# LM3S1969 register map
File version: 7944
Registers are 32-bit, read-write, no defined reset value unless marked. A register's access mark holds for its fields unless they carry their own. Offsets are from the block's base; [hi:lo] are bit positions; {n}, {i} and the like mark numbered series.

## ADC0 — Register map for ADC0 peripheral
Base 0x40038000; register names take the prefix ADC0
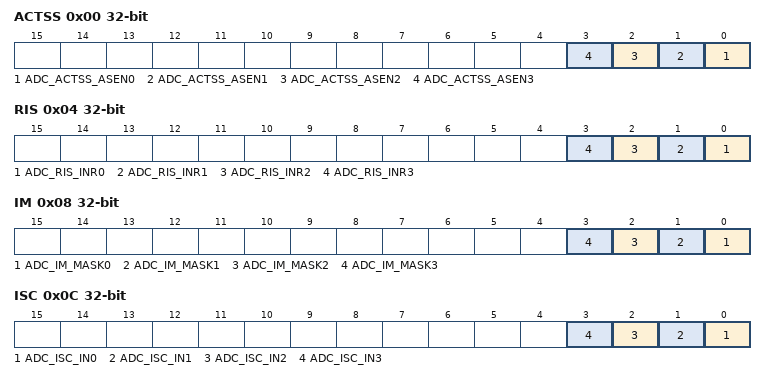
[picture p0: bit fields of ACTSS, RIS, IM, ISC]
0x00 ACTSS — ADC Active Sample Sequencer
  [n] ADC_ACTSS_ASEN{n} (n=0..3) — ADC SS{n} Enable
0x04 RIS — ADC Raw Interrupt Status
  [n] ADC_RIS_INR{n} (n=0..3) — SS{n} Raw Interrupt Status
0x08 IM — ADC Interrupt Mask
  [n] ADC_IM_MASK{n} (n=0..3) — SS{n} Interrupt Mask
0x0C ISC — ADC Interrupt Status and Clear
  [n] ADC_ISC_IN{n} (n=0..3) — SS{n} Interrupt Status and Clear
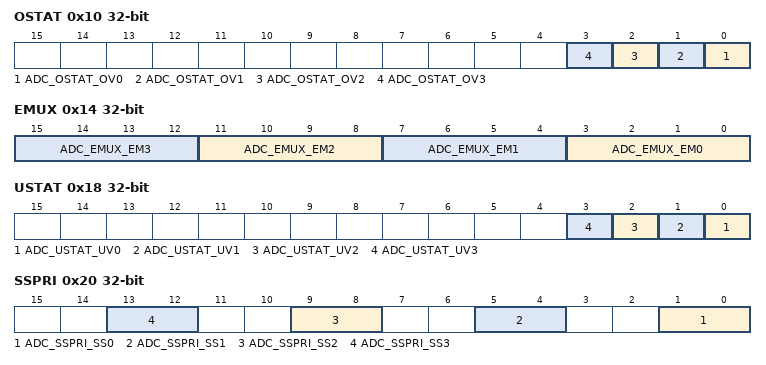
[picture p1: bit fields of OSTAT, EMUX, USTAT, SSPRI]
0x10 OSTAT — ADC Overflow Status
  [n] ADC_OSTAT_OV{n} (n=0..3) — SS{n} FIFO Overflow
0x14 EMUX — ADC Event Multiplexer Select
  [4n+3:4n] ADC_EMUX_EM{n} (n=0..3) — SS{n} Trigger Select
    0=ADC_EMUX_EM{n}_PROCESSOR (Processor (default)); 1=ADC_EMUX_EM{n}_COMP0 (Analog Comparator 0); 2=ADC_EMUX_EM{n}_COMP1 (Analog Comparator 1); 3=ADC_EMUX_EM{n}_COMP2 (Analog Comparator 2); 4=ADC_EMUX_EM{n}_EXTERNAL (External (GPIO PB4)); 5=ADC_EMUX_EM{n}_TIMER (Timer); 6=ADC_EMUX_EM{n}_PWM0 (PWM0); 7=ADC_EMUX_EM{n}_PWM1 (PWM1); 8=ADC_EMUX_EM{n}_PWM2 (PWM2); 15=ADC_EMUX_EM{n}_ALWAYS (Always (continuously sample))
0x18 USTAT — ADC Underflow Status
  [n] ADC_USTAT_UV{n} (n=0..3) — SS{n} FIFO Underflow
0x20 SSPRI — ADC Sample Sequencer Priority
  [4n+1:4n] ADC_SSPRI_SS{n} (n=0..3) — SS{n} Priority
    0=ADC_SSPRI_SS{n}_1ST (First priority); 1=ADC_SSPRI_SS{n}_2ND (Second priority); 2=ADC_SSPRI_SS{n}_3RD (Third priority); 3=ADC_SSPRI_SS{n}_4TH (Fourth priority)
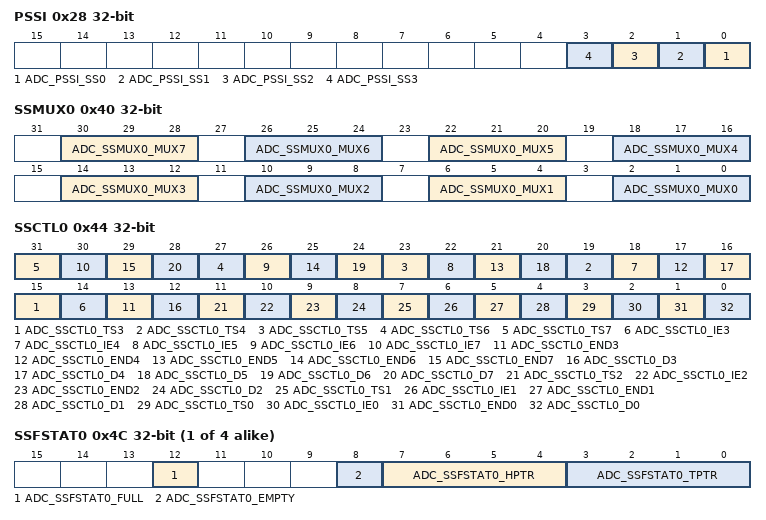
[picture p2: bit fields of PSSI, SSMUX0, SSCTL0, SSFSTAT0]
0x28 PSSI — ADC Processor Sample Sequence Initiate
  [n] ADC_PSSI_SS{n} (n=0..3) — SS{n} Initiate
0x30 SAC — ADC Sample Averaging Control
  [2:0] ADC_SAC_AVG — Hardware Averaging Control
    0=ADC_SAC_AVG_OFF (No hardware oversampling); 1=ADC_SAC_AVG_2X (2x hardware oversampling); 2=ADC_SAC_AVG_4X (4x hardware oversampling); 3=ADC_SAC_AVG_8X (8x hardware oversampling); 4=ADC_SAC_AVG_16X (16x hardware oversampling); 5=ADC_SAC_AVG_32X (32x hardware oversampling); 6=ADC_SAC_AVG_64X (64x hardware oversampling)
0x40 SSMUX0 — ADC Sample Sequence Input Multiplexer Select 0
  [4n+2:4n] ADC_SSMUX0_MUX{n} (n=3..7) — {n+1}th Sample Input Select
  [10:8] ADC_SSMUX0_MUX2 — 3rd Sample Input Select
  [6:4] ADC_SSMUX0_MUX1 — 2nd Sample Input Select
  [2:0] ADC_SSMUX0_MUX0 — 1st Sample Input Select
0x44 SSCTL0 — ADC Sample Sequence Control 0
  [4n+3] ADC_SSCTL0_TS{n} (n=3..7) — {n+1}th Sample Temp Sensor Select
  [4n+2] ADC_SSCTL0_IE{n} (n=3..7) — {n+1}th Sample Interrupt Enable
  [4n+1] ADC_SSCTL0_END{n} (n=3..7) — {n+1}th Sample is End of Sequence
  [4n] ADC_SSCTL0_D{n} (n=3..7) — {n+1}th Sample Diff Input Select
  [11] ADC_SSCTL0_TS2 — 3rd Sample Temp Sensor Select
  [10] ADC_SSCTL0_IE2 — 3rd Sample Interrupt Enable
  [9] ADC_SSCTL0_END2 — 3rd Sample is End of Sequence
  [8] ADC_SSCTL0_D2 — 3rd Sample Diff Input Select
  [7] ADC_SSCTL0_TS1 — 2nd Sample Temp Sensor Select
  [6] ADC_SSCTL0_IE1 — 2nd Sample Interrupt Enable
  [5] ADC_SSCTL0_END1 — 2nd Sample is End of Sequence
  [4] ADC_SSCTL0_D1 — 2nd Sample Diff Input Select
  [3] ADC_SSCTL0_TS0 — 1st Sample Temp Sensor Select
  [2] ADC_SSCTL0_IE0 — 1st Sample Interrupt Enable
  [1] ADC_SSCTL0_END0 — 1st Sample is End of Sequence
  [0] ADC_SSCTL0_D0 — 1st Sample Diff Input Select
{0x48+0x20*i} SSFIFO{i} (i=0..3) — ADC Sample Sequence Result FIFO {i}
  [9:0] ADC_SSFIFO{i}_DATA — Conversion Result Data
{0x4C+0x20*i} SSFSTAT{i} (i=0..3) — ADC Sample Sequence FIFO {i} Status
  [12] ADC_SSFSTAT{i}_FULL — FIFO Full
  [8] ADC_SSFSTAT{i}_EMPTY — FIFO Empty
  [7:4] ADC_SSFSTAT{i}_HPTR — FIFO Head Pointer
  [3:0] ADC_SSFSTAT{i}_TPTR — FIFO Tail Pointer
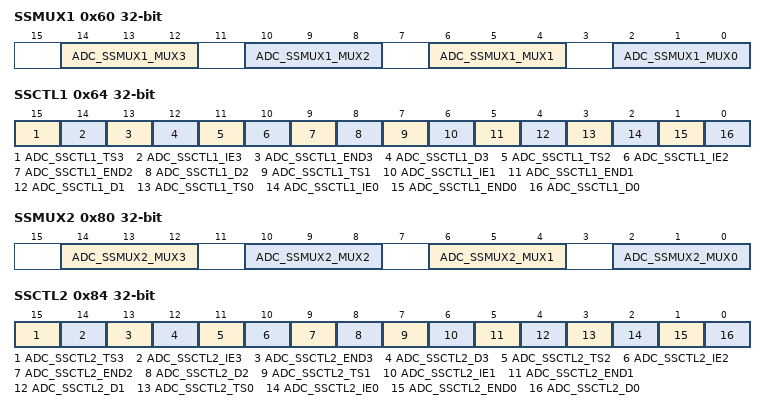
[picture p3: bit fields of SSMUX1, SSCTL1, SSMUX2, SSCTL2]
0x60 SSMUX1 — ADC Sample Sequence Input Multiplexer Select 1
  [14:12] ADC_SSMUX1_MUX3 — 4th Sample Input Select
  [10:8] ADC_SSMUX1_MUX2 — 3rd Sample Input Select
  [6:4] ADC_SSMUX1_MUX1 — 2nd Sample Input Select
  [2:0] ADC_SSMUX1_MUX0 — 1st Sample Input Select
0x64 SSCTL1 — ADC Sample Sequence Control 1
  [15] ADC_SSCTL1_TS3 — 4th Sample Temp Sensor Select
  [14] ADC_SSCTL1_IE3 — 4th Sample Interrupt Enable
  [13] ADC_SSCTL1_END3 — 4th Sample is End of Sequence
  [12] ADC_SSCTL1_D3 — 4th Sample Diff Input Select
  [11] ADC_SSCTL1_TS2 — 3rd Sample Temp Sensor Select
  [10] ADC_SSCTL1_IE2 — 3rd Sample Interrupt Enable
  [9] ADC_SSCTL1_END2 — 3rd Sample is End of Sequence
  [8] ADC_SSCTL1_D2 — 3rd Sample Diff Input Select
  [7] ADC_SSCTL1_TS1 — 2nd Sample Temp Sensor Select
  [6] ADC_SSCTL1_IE1 — 2nd Sample Interrupt Enable
  [5] ADC_SSCTL1_END1 — 2nd Sample is End of Sequence
  [4] ADC_SSCTL1_D1 — 2nd Sample Diff Input Select
  [3] ADC_SSCTL1_TS0 — 1st Sample Temp Sensor Select
  [2] ADC_SSCTL1_IE0 — 1st Sample Interrupt Enable
  [1] ADC_SSCTL1_END0 — 1st Sample is End of Sequence
  [0] ADC_SSCTL1_D0 — 1st Sample Diff Input Select
0x80 SSMUX2 — ADC Sample Sequence Input Multiplexer Select 2
  [14:12] ADC_SSMUX2_MUX3 — 4th Sample Input Select
  [10:8] ADC_SSMUX2_MUX2 — 3rd Sample Input Select
  [6:4] ADC_SSMUX2_MUX1 — 2nd Sample Input Select
  [2:0] ADC_SSMUX2_MUX0 — 1st Sample Input Select
0x84 SSCTL2 — ADC Sample Sequence Control 2
  [15] ADC_SSCTL2_TS3 — 4th Sample Temp Sensor Select
  [14] ADC_SSCTL2_IE3 — 4th Sample Interrupt Enable
  [13] ADC_SSCTL2_END3 — 4th Sample is End of Sequence
  [12] ADC_SSCTL2_D3 — 4th Sample Diff Input Select
  [11] ADC_SSCTL2_TS2 — 3rd Sample Temp Sensor Select
  [10] ADC_SSCTL2_IE2 — 3rd Sample Interrupt Enable
  [9] ADC_SSCTL2_END2 — 3rd Sample is End of Sequence
  [8] ADC_SSCTL2_D2 — 3rd Sample Diff Input Select
  [7] ADC_SSCTL2_TS1 — 2nd Sample Temp Sensor Select
  [6] ADC_SSCTL2_IE1 — 2nd Sample Interrupt Enable
  [5] ADC_SSCTL2_END1 — 2nd Sample is End of Sequence
  [4] ADC_SSCTL2_D1 — 2nd Sample Diff Input Select
  [3] ADC_SSCTL2_TS0 — 1st Sample Temp Sensor Select
  [2] ADC_SSCTL2_IE0 — 1st Sample Interrupt Enable
  [1] ADC_SSCTL2_END0 — 1st Sample is End of Sequence
  [0] ADC_SSCTL2_D0 — 1st Sample Diff Input Select
0xA0 SSMUX3 — ADC Sample Sequence Input Multiplexer Select 3
  [2:0] ADC_SSMUX3_MUX0 — 1st Sample Input Select
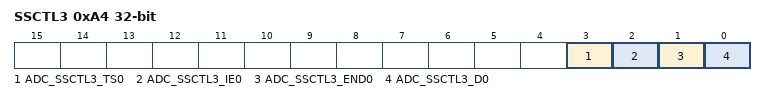
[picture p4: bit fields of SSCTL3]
0xA4 SSCTL3 — ADC Sample Sequence Control 3
  [3] ADC_SSCTL3_TS0 — 1st Sample Temp Sensor Select
  [2] ADC_SSCTL3_IE0 — 1st Sample Interrupt Enable
  [1] ADC_SSCTL3_END0 — 1st Sample is End of Sequence
  [0] ADC_SSCTL3_D0 — 1st Sample Diff Input Select
0x100 TMLB — ADC Test Mode Loopback
  [0] ADC_TMLB_LB — Loopback Mode Enable
